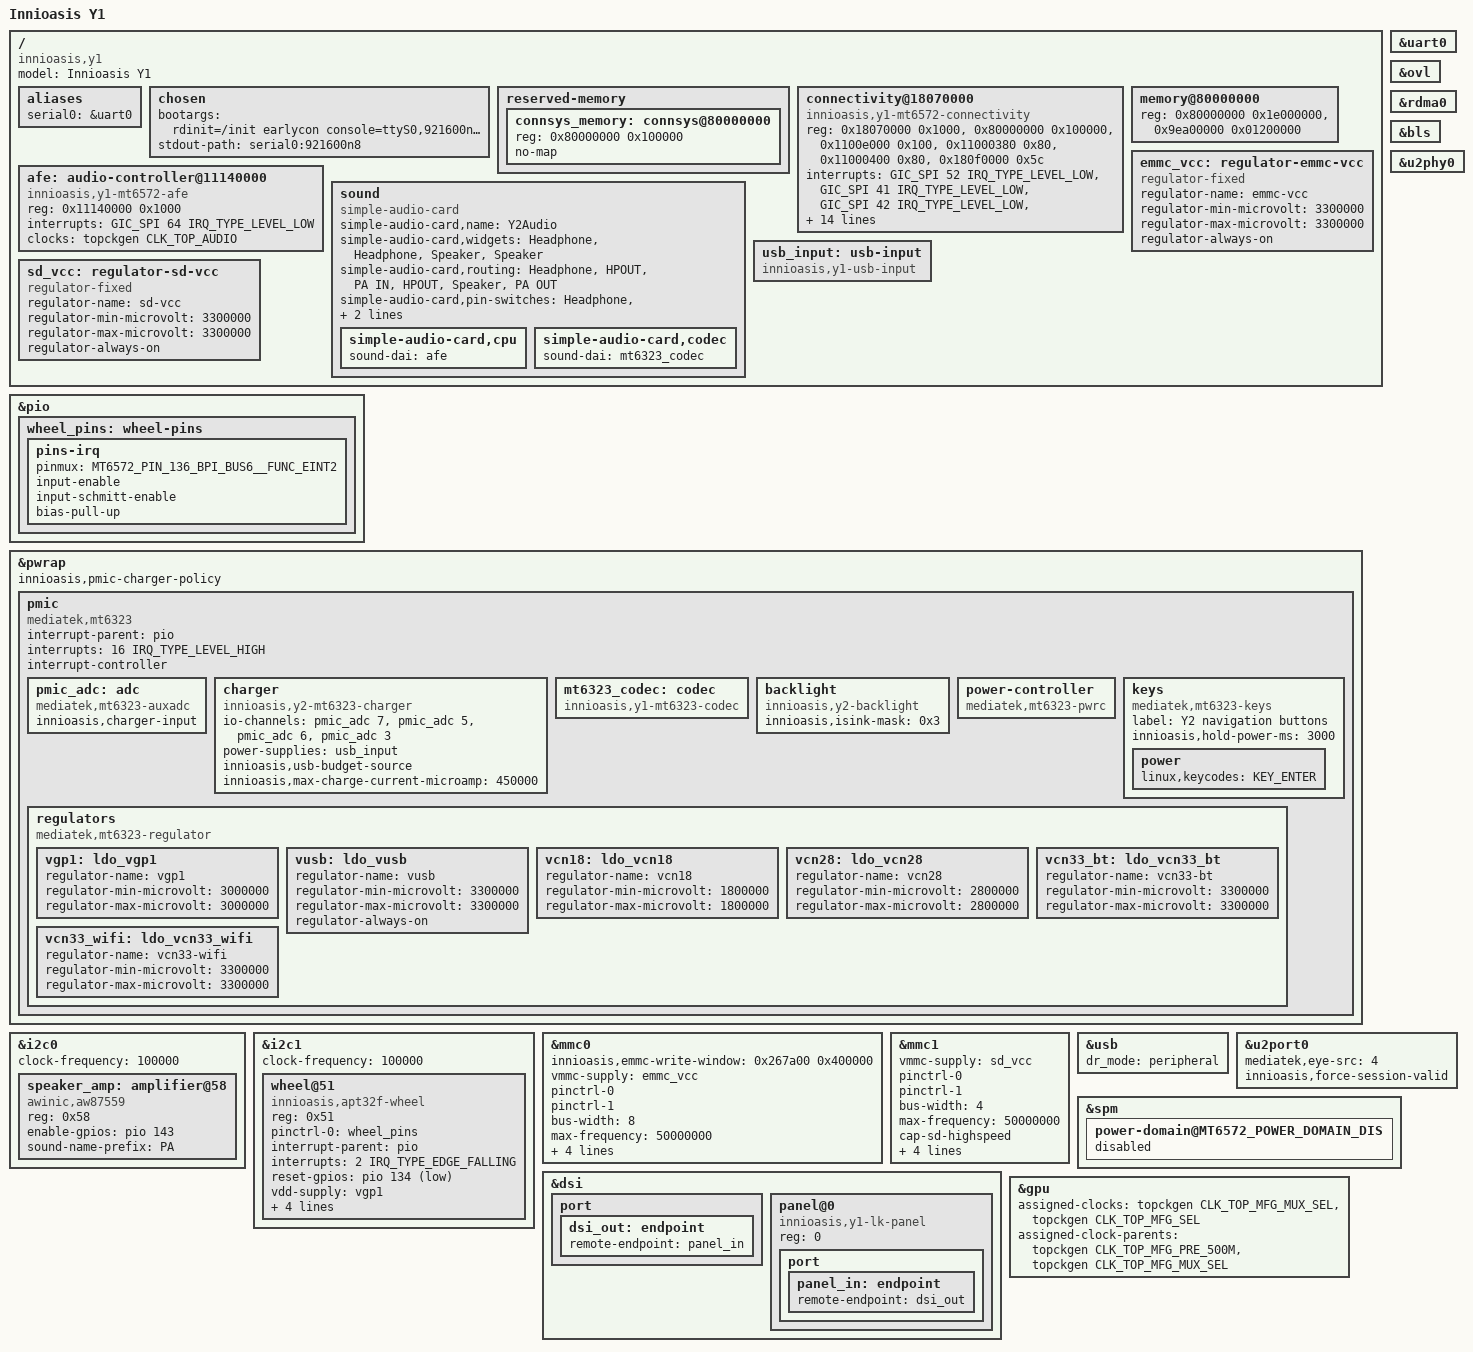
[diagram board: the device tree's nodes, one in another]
// SPDX-License-Identifier: GPL-2.0-only
/*
 * Innioasis Y1 (MT6572) device tree. Facts: docs/knowledge/y1-hardware.md; each subsystem's plan and hardware
 * evidence in docs/planning/Y1-*-PLAN.md.
 *
 * - Clocks, pins, the PMIC wrapper and its charger-block write policy, UART0 at 921600 baud, both CPUs (their
 *   enable-method in mt6572-fork.dtsi).
 * - Storage: the eMMC (writes only inside the write guard's USRDATA window, Y2DATA) and the microSD card; the two
 *   card supplies are fixed descriptions, not PMIC regulators.
 * - Input: the APT32F wheel on I2C1, its zones on their own input device "Y2 navigation buttons" (play/pause,
 *   next, back, previous as KEY_PLAYPAUSE, KEY_RIGHT, KEY_BACK, KEY_LEFT), and the centre button (MT6323 power
 *   key) under the same name, so it is Select; a 3 s hold is also KEY_POWER (Reborn's Power).
 * - USB in device mode, the MT6323 AUXADC, the MT6323 charger (the Y2's driver, PC port only, at most 450 mA,
 *   4.175 V) with the Y1 USB budget source it charges from, and the MT6323 power controller (power-off through
 *   the RTC BBPU).
 * - Display: the MediaTek DRM pipeline OVL -> RDMA -> COLOR -> BLS -> DSI with LK's panel adopted as initialised
 *   (no reset, no command, backlight untouched), physical scan-out (no IOMMU); the backlight on MT6323 ISINK0/1
 *   (the shared Y2 driver, never above LK's duty); the Y2's console level (loglevel=3) and no cursor before the
 *   splash.
 * - GPU: the SPM power controller with only the MFG domain (the display domain stays as LK left it), Mali-400
 *   clocked from WHPLL at 500.5 MHz as stock, no OPP table, no MFG reset.
 * - Audio: the MT6572 AFE (DL1 -> ADDA), the MT6323 codec and the AW87559 speaker amplifier on I2C0, fed from the
 *   MT6323's HPOUT, in a simple card named as Reborn expects ("Y2Audio", pins "Headphone" and "Speaker").
 * - Connectivity: the core's memory reserved (0x80000000, 1 MiB, no-map), the MT6572 connectivity owner with its
 *   supplies VCN18, VCN28 and the PA supplies VCN33_BT/VCN33_WIFI (none always-on or boot-on): hci0 once userspace
 *   hands it the 32-byte BT_Addr record and activates it; with the Wi-Fi record handed over before activation,
 *   the fullmac's device (MediaTek's CONN_HIF_BASE 0x180f0000 and MT_WF_HIF_IRQ_ID, SPI 123) and its rfkill
 *   switch, blocked; unblocking it boots the Wi-Fi firmware (firmware_class.path=/data/firmware).
 * Deliberately absent: USB host mode and every PMIC regulator not listed above.
 */
/dts-v1/;
#include <dt-bindings/gpio/gpio.h>
#include <dt-bindings/input/input.h>
#include "mt6572-fork.dtsi"

/ {
	model = "Innioasis Y1";
	compatible = "innioasis,y1", "mediatek,mt6572";

	aliases {
		serial0 = &uart0;
	};

	chosen {
		#address-cells = <1>;
		#size-cells = <1>;
		ranges;
		/* clk_ignore_unused: the clock driver must not gate the display clocks LK left running.
		 * firmware_class.path: the owner's radio files on Y2DATA (/data, mounted at about 2.3 s; the
		 * B5 attempt is started later from userspace), searched before /lib/firmware. */
		bootargs = "rdinit=/init earlycon console=ttyS0,921600n8 console=tty0 loglevel=3 vt.global_cursor_default=0 panic=10 clk_ignore_unused firmware_class.path=/data/firmware";
		stdout-path = "serial0:921600n8";
	};

	/* The MT6572 connectivity core's fixed memory (stock 3.0.2 too); the kernel runs at 0x80108000. */
	reserved-memory {
		#address-cells = <1>;
		#size-cells = <1>;
		ranges;

		connsys_memory: connsys@80000000 {
			reg = <0x80000000 0x100000>;
			no-map;
		};
	};

	/*
	 * The connectivity core (driver kernel/y1/connectivity/, the fixed wiring of y1-conn-policy.h, which the
	 * probe checks): the full driver (B6). No power at probe; userspace writes the record to "factory" and 1 to
	 * "activate"; hci0 up runs the B5 boot (BTIF/DMA, patch, calibration), hci0 down WMT sleep and power-off.
	 */
	connectivity@18070000 {
		compatible = "innioasis,y1-mt6572-connectivity";
		reg = <0x18070000 0x1000>, <0x80000000 0x100000>, <0x1100e000 0x100>,
		      <0x11000380 0x80>, <0x11000400 0x80>, <0x180f0000 0x5c>;
		reg-names = "mcu", "conn-emi", "btif", "tx-dma", "rx-dma", "wifi";
		interrupts = <GIC_SPI 52 IRQ_TYPE_LEVEL_LOW>, <GIC_SPI 41 IRQ_TYPE_LEVEL_LOW>,
			     <GIC_SPI 42 IRQ_TYPE_LEVEL_LOW>, <GIC_SPI 122 IRQ_TYPE_LEVEL_LOW>,
			     <GIC_SPI 123 IRQ_TYPE_LEVEL_LOW>;
		interrupt-names = "btif", "tx-dma", "rx-dma", "wake", "wifi";
		clocks = <&topckgen CLK_TOP_SPM>, <&topckgen CLK_TOP_BTIF>, <&topckgen CLK_TOP_APDMA>;
		clock-names = "spm", "btif", "dma";
		vcn18-supply = <&vcn18>;
		vcn28-supply = <&vcn28>;
		vcn33-bt-supply = <&vcn33_bt>;
		vcn33-wifi-supply = <&vcn33_wifi>;
		innioasis,pwrap = <&pwrap>;
		innioasis,scpsys = <&{/soc/power-controller@10006000}>;
		mediatek,infracfg = <&infracfg>;
		memory-region = <&connsys_memory>;
		status = "okay";
	};

	/* Confirmed on the Y1 (docs/knowledge/y1-hardware.md): stock System RAM; the 10 MiB at 0x9e000000 and the
	 * frame buffer stay out. */
	memory@80000000 {
		device_type = "memory";
		reg = <0x80000000 0x1e000000>, <0x9ea00000 0x01200000>;
	};

	/*
	 * Not PMIC regulators: fixed descriptions of the card rails LK leaves on (stock: VEMC_3V3 at 3.3 V),
	 * so mtk-sd knows their voltage. Without a vmmc supply it accepts no card voltage at all (second
	 * boot run 1: "no support for card's volts"). Linux switches nothing here.
	 */
	emmc_vcc: regulator-emmc-vcc {
		compatible = "regulator-fixed";
		regulator-name = "emmc-vcc";
		regulator-min-microvolt = <3300000>;
		regulator-max-microvolt = <3300000>;
		regulator-always-on;
	};

	/* Stock AudDrv: AFE at 0x11140000, IRQ 96 = SPI 64 level low, clock MT_CG_AUDIO_SW_CG. */
	afe: audio-controller@11140000 {
		compatible = "innioasis,y1-mt6572-afe";
		reg = <0x11140000 0x1000>;
		interrupts = <GIC_SPI 64 IRQ_TYPE_LEVEL_LOW>;
		clocks = <&topckgen CLK_TOP_AUDIO>;
		clock-names = "audio";
		#sound-dai-cells = <0>;
	};

	sound {
		compatible = "simple-audio-card";
		simple-audio-card,name = "Y2Audio";
		simple-audio-card,widgets = "Headphone", "Headphone", "Speaker", "Speaker";
		/* Stock: the AW87559 is fed from the MT6323's headphone outputs. */
		simple-audio-card,routing = "Headphone", "HPOUT", "PA IN", "HPOUT", "Speaker", "PA OUT";
		simple-audio-card,pin-switches = "Headphone", "Speaker";
		simple-audio-card,aux-devs = <&speaker_amp>;

		simple-audio-card,cpu {
			sound-dai = <&afe>;
		};

		simple-audio-card,codec {
			sound-dai = <&mt6323_codec>;
		};
	};

	/* The configured USB budget, reported by the gadget (kernel/y1/usb-source.c). */
	usb_input: usb-input {
		compatible = "innioasis,y1-usb-input";
	};

	sd_vcc: regulator-sd-vcc {
		compatible = "regulator-fixed";
		regulator-name = "sd-vcc";
		regulator-min-microvolt = <3300000>;
		regulator-max-microvolt = <3300000>;
		regulator-always-on;
	};
};

&pio {
	/* Stock 3.0.2 tpd_probe: GPIO136 mode 4 (EINT2), direction input, pull enabled and up. On paris
	 * input-enable sets only the input buffer; input-schmitt-enable is what sets the direction to input
	 * (run 3: "tried to flag a GPIO set as output for IRQ"). */
	wheel_pins: wheel-pins {
		pins-irq {
			pinmux = <MT6572_PIN_136_BPI_BUS6__FUNC_EINT2>;
			input-enable;
			input-schmitt-enable;
			bias-pull-up;
		};
	};
};

&pwrap {
	/* Charger block writes only within the Y2's reviewed fields and values (policy.h). */
	innioasis,pmic-charger-policy;

	/* Not upstream mt6323.dtsi: that describes every regulator, and Linux may switch off any described,
	 * unused one. Only the power key and VGP1 exist here; the others stay as LK left them. */
	pmic: pmic {
		compatible = "mediatek,mt6323";
		/* Stock PMIC_EINT_SETTING: EINT16, level, active high. */
		interrupt-parent = <&pio>;
		interrupts = <16 IRQ_TYPE_LEVEL_HIGH>;
		interrupt-controller;
		#interrupt-cells = <2>;

		/* Read-only telemetry; the Y1 adds the charger input (VCDT, channel 4). */
		pmic_adc: adc {
			compatible = "mediatek,mt6323-auxadc";
			#io-channel-cells = <1>;
			innioasis,charger-input;
		};

		/*
		 * The Y2's charger with Y1 limits: no BC1.1 (every source is a PC port; 450 mA only once a
		 * PC has configured the gadget, 70 mA otherwise); 4.175 V; PMIC die derating; the PMIC
		 * charger watchdog. No pack temperature (BATON does not respond, charging plan section 9) and no
		 * power-off-to-charger path (no innioasis,rgu: LK's charging mode is unverified on the Y1).
		 */
		charger {
			compatible = "innioasis,y2-mt6323-charger";
			io-channels = <&pmic_adc 7>, <&pmic_adc 5>, <&pmic_adc 6>, <&pmic_adc 3>;
			io-channel-names = "battery-voltage", "baton", "isense", "pmic-temperature";
			power-supplies = <&usb_input>;
			innioasis,usb-budget-source;
			innioasis,max-charge-current-microamp = <450000>;
		};

		/* The MT6323's audio codec, headphone path (the AW87559 speaker path is stage C). */
		mt6323_codec: codec {
			compatible = "innioasis,y1-mt6323-codec";
			#sound-dai-cells = <0>;
		};

		/* Stock lcd-backlight: MT6323 PMIC mode, ISINK0 and ISINK1 in parallel (display stage 0). */
		backlight {
			compatible = "innioasis,y2-backlight";
			innioasis,isink-mask = <0x3>;
		};

		/* Power-off only: BBPU 0x4300 and WRTGR 1 at power-off (no RTC driver). */
		power-controller {
			compatible = "mediatek,mt6323-pwrc";
		};

		keys {
			compatible = "mediatek,mt6323-keys";
			label = "Y2 navigation buttons";
			/* Held this long, the centre button is also Reborn's Power (overlay 0033). */
			innioasis,hold-power-ms = <3000>;
			/* The centre button (the Y1 has no power button). */
			power {
				linux,keycodes = <KEY_ENTER>;
			};
		};

		regulators {
			compatible = "mediatek,mt6323-regulator";

			/* The wheel controller's supply; stock hwPowerOn(5, 3000, "TP"). */
			vgp1: ldo_vgp1 {
				regulator-name = "vgp1";
				regulator-min-microvolt = <3000000>;
				regulator-max-microvolt = <3000000>;
			};

			/* The USB PHY's analogue supply; stock hwPowerOn(1, 3300, "VUSB_LDO") at USB init and
			 * never switched off. */
			vusb: ldo_vusb {
				regulator-name = "vusb";
				regulator-min-microvolt = <3300000>;
				regulator-max-microvolt = <3300000>;
				regulator-always-on;
			};

			/* The connectivity core's supplies (stock hwPowerOn(8 = VCN_1V8) and (24 = VCN28), fixed
			 * 1.8 V / 2.8 V; enables 0x512 bit 14 and 0x41c bit 12). Off as LK leaves them, so the late
			 * regulator cleanup finds nothing to switch off; no always-on, no boot-on. */
			vcn18: ldo_vcn18 {
				regulator-name = "vcn18";
				regulator-min-microvolt = <1800000>;
				regulator-max-microvolt = <1800000>;
			};

			vcn28: ldo_vcn28 {
				regulator-name = "vcn28";
				regulator-min-microvolt = <2800000>;
				regulator-max-microvolt = <2800000>;
			};

			/* The PA supplies (stock hwPowerOn(22/23, 3300 mV) for the RF calibration only; enables
			 * 0x416 bit 7 and 0x418 bit 12, a shared VOSEL 0x416 [3:2]). Off as LK leaves them; fixed
			 * at 3.3 V, so the regulator core sets that VOSEL (LK's 3, 3.6 V) to 0 at boot with both
			 * rails off, as stock's hwPowerOn would. No always-on, no boot-on. */
			vcn33_bt: ldo_vcn33_bt {
				regulator-name = "vcn33-bt";
				regulator-min-microvolt = <3300000>;
				regulator-max-microvolt = <3300000>;
			};

			vcn33_wifi: ldo_vcn33_wifi {
				regulator-name = "vcn33-wifi";
				regulator-min-microvolt = <3300000>;
				regulator-max-microvolt = <3300000>;
			};
		};
	};
};

/* The speaker amplifier only (stock: 0-0058 aw87559_pa). */
&i2c0 {
	status = "okay";
	clock-frequency = <100000>;

	/* Stock aw87559_i2c_probe: GPIO143 enables it; low, the default, it is off and does not answer. */
	speaker_amp: amplifier@58 {
		compatible = "awinic,aw87559";
		reg = <0x58>;
		enable-gpios = <&pio 143 GPIO_ACTIVE_HIGH>;
		sound-name-prefix = "PA";
	};
};

&i2c1 {
	status = "okay";
	clock-frequency = <100000>;

	wheel@51 {
		compatible = "innioasis,apt32f-wheel";
		reg = <0x51>;
		pinctrl-names = "default";
		pinctrl-0 = <&wheel_pins>;
		interrupt-parent = <&pio>;
		interrupts = <2 IRQ_TYPE_EDGE_FALLING>;
		reset-gpios = <&pio 134 GPIO_ACTIVE_LOW>;
		vdd-supply = <&vgp1>;
		/* reg3 bits 0-3: bottom, right, top, left (owner's getevent of stock 3.0.2). */
		linux,keycodes = <KEY_PLAYPAUSE KEY_RIGHT KEY_BACK KEY_LEFT>;
		/* Reborn takes select, back, left/right and play/pause only from this device name. */
		innioasis,zone-input-name = "Y2 navigation buttons";
	};
};

/*
 * Storage, read by the test PID1 only: no filesystem driver is built, PID1 sets each disk read-only
 * before reading. Conservative bus modes, no supplies (LK leaves them on), and empty pin states that
 * keep the preloader's pin setup (mtk-sd requires both states to exist).
 */
&mmc0 {
	status = "okay";
	/* The eMMC write guard (kernel/y1/emmc-guard.h): writes only to USRDATA, physical 0x4cf40000 (sector
	 * 0x267a00), 2 GiB (0x400000 sectors). PID1 makes the eMMC writable only when this window is present. */
	innioasis,emmc-write-window = <0x267a00 0x400000>;
	vmmc-supply = <&emmc_vcc>;
	pinctrl-names = "default", "state_uhs";
	pinctrl-0;
	pinctrl-1;
	bus-width = <8>;
	max-frequency = <50000000>;
	cap-mmc-highspeed;
	non-removable;
	no-sd;
	no-sdio;
};

&mmc1 {
	status = "okay";
	vmmc-supply = <&sd_vcc>;
	pinctrl-names = "default", "state_uhs";
	pinctrl-0;
	pinctrl-1;
	bus-width = <4>;
	max-frequency = <50000000>;
	cap-sd-highspeed;
	/* Card-detect pin unknown: probe once at boot (broken-cd polled every second and flooded the
	 * screen in run 1). A card must be inserted before power-on. */
	non-removable;
	no-1-8-v;
	no-mmc;
	no-sdio;
};

&uart0 {
	status = "okay";
};

/* Display stage B: physical scan-out, as LK; no IOMMU driver is built. */
&ovl {
	/delete-property/ iommus;
};

&rdma0 {
	/delete-property/ iommus;
};

/* In the path as a pass-through; its PWM driver is not built and the backlight comes from the MT6323. */
&bls {
	status = "okay";
};

&dsi {
	status = "okay";
	#address-cells = <1>;
	#size-cells = <0>;

	/* 6.18's mtk_dsi_host_attach finds its panel only through an OF graph (Y1-DISPLAY-PLAN.md, stage B run 1:
	 * "error -19: DSI attach" with a bare child node). */
	port {
		dsi_out: endpoint {
			remote-endpoint = <&panel_in>;
		};
	};

	panel@0 {
		compatible = "innioasis,y1-lk-panel";
		reg = <0>;

		port {
			panel_in: endpoint {
				remote-endpoint = <&dsi_out>;
			};
		};
	};
};

/* Device mode only: no host mode, no role switch, nothing drives VBUS. PIO only (no DMA) by config. */
&usb {
	status = "okay";
	dr_mode = "peripheral";
};

&u2phy0 {
	status = "okay";
};

/*
 * Mainline's v1 T-PHY calibrates the slew rate with a frequency meter at sif + 0x100 (0x11110100); the
 * MT6572's meter is at 0x11110f00 (stock hs_slew_rate_cal). A fixed eye-src skips that calibration; 4
 * is what stock writes when its own calibration times out.
 */
&u2port0 {
	mediatek,eye-src = <4>;
	/* USB bring-up (docs/knowledge/y1-hardware.md): with only mainline's RG_VBUSVALID/RG_AVALID the controller stayed "not
	 * attached" while the PMIC measured 5.2 V on VCDT. Stock usb_phy_recover forces the whole session
	 * (U2PHYDTM1 |= 0x2e, SESSEND clear, force bits 9-13); patches-y1 0015 does the same on this flag. */
	innioasis,force-session-valid;
};

/* The display domain is LK's: Linux would power an unclaimed domain off at late init (dark screen). */
&spm {
	power-domain@MT6572_POWER_DOMAIN_DIS {
		status = "disabled";
	};
};

/*
 * Stock 3.0.2 runs this chip's GPU (eFuse 0x10009178 bit 27 = 0) from WHPLL at 500.5 MHz: mfg_mux_sel on
 * mfg_pre_500m, mfg_sel on the mux. WHPLL keeps LK's divider (500.5 MHz); no rate is set. Stock never uses the
 * MFG reset, and without an OPP table Lima's devfreq stays off.
 */
&gpu {
	/delete-property/ resets;
	assigned-clocks = <&topckgen CLK_TOP_MFG_MUX_SEL>, <&topckgen CLK_TOP_MFG_SEL>;
	assigned-clock-parents = <&topckgen CLK_TOP_MFG_PRE_500M>, <&topckgen CLK_TOP_MFG_MUX_SEL>;
};
